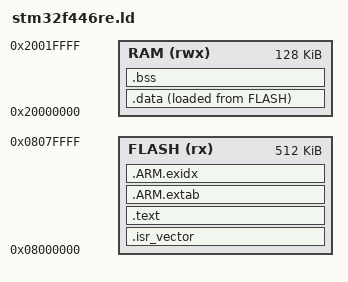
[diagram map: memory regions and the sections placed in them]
ENTRY(Reset_Handler)

MEMORY
{
    FLASH (rx) : ORIGIN = 0x08000000, LENGTH = 512K
    RAM (rwx)  : ORIGIN = 0x20000000, LENGTH = 128K
}

_estack = ORIGIN(RAM) + LENGTH(RAM);
_stack_limit = _estack - 8K;

SECTIONS
{
    .isr_vector : { KEEP(*(.isr_vector)) } > FLASH
    .text : { *(.text*) *(.rodata*) KEEP(*(.init)) KEEP(*(.fini)) . = ALIGN(4); } > FLASH
    .ARM.extab : { *(.ARM.extab*) } > FLASH
    .ARM.exidx : { __exidx_start = .; *(.ARM.exidx*) __exidx_end = .; } > FLASH
    .data : {
        . = ALIGN(4); _sdata = .; *(.data*) . = ALIGN(4); _edata = .;
    } > RAM AT > FLASH
    _sidata = LOADADDR(.data);
    .bss (NOLOAD) : {
        . = ALIGN(8); _sbss = .; *(.bss*) *(COMMON) . = ALIGN(8); _ebss = .;
    } > RAM
    _end = .;
    ASSERT(_end < _stack_limit, "RAM exhausted: no space for heap and stack")
}
